# EFR32FG23B021F512IM48 register map
Vendor: Silicon Labs; Series: EFR32; File version: C
CPU: CM33 r0p4, little endian, MPU, FPU, DSP, VTOR, 4 interrupt priority bits, 8 SAU regions
Registers are 32-bit, read-write, reset 0x0 unless marked. A register's access mark holds for its fields unless they carry their own. Offsets are from the block's base; [hi:lo] are bit positions; {n}, {i} and the like mark numbered series; 'fields as' and 'values as' point back to an identical list.

## BURAM_NS — BURAM_NS Registers
Base 0x50080000
Same registers: BURAM_S 0x40080000
{0x0+4i} RET{i}_REG (i=0..31)
  [31:0] RETREG — Latch based Retention register

## BURTC_NS — BURTC_NS Registers
Base 0x50064000
Same registers: BURTC_S 0x40064000
0x00 IPVERSION ro reset 0x1
  [31:0] IPVERSION — IP Version ID
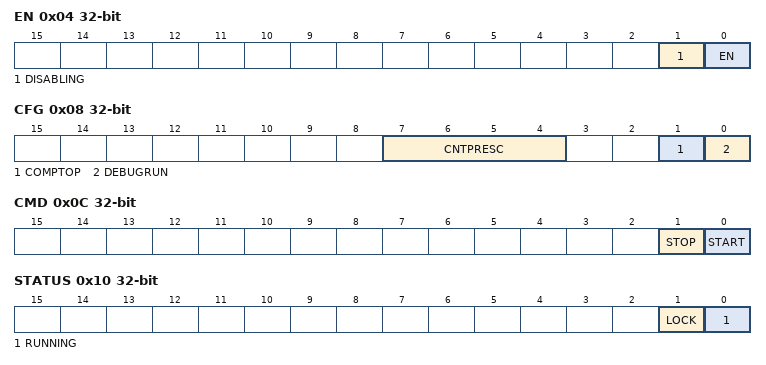
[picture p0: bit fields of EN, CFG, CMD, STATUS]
0x04 EN
  [1] DISABLING ro — Disablement busy status
  [0] EN — BURTC Enable
0x08 CFG
  [7:4] CNTPRESC — Counter prescaler value.
    0=DIV1 (CLK_CNT = (BURTC LF CLK)/1); 1=DIV2 (CLK_CNT = (BURTC LF CLK)/2); 2=DIV4 (CLK_CNT = (BURTC LF CLK)/4); 3=DIV8 (CLK_CNT = (BURTC LF CLK)/8); 4=DIV16 (CLK_CNT = (BURTC LF CLK)/16); 5=DIV32 (CLK_CNT = (BURTC LF CLK)/32); 6=DIV64 (CLK_CNT = (BURTC LF CLK)/64); 7=DIV128 (CLK_CNT = (BURTC LF CLK)/128); 8=DIV256 (CLK_CNT = (BURTC LF CLK)/256); 9=DIV512 (CLK_CNT = (BURTC LF CLK)/512); 10=DIV1024 (CLK_CNT = (BURTC LF CLK)/1024); 11=DIV2048 (CLK_CNT = (BURTC LF CLK)/2048); 12=DIV4096 (CLK_CNT = (BURTC LF CLK)/4096); 13=DIV8192 (CLK_CNT = (BURTC LF CLK)/8192); 14=DIV16384 (CLK_CNT = (BURTC LF CLK)/16384); 15=DIV32768 (CLK_CNT = (BURTC LF CLK)/32768)
  [1] COMPTOP — Compare Channel is Top Value
    0=DISABLE (The top value of the BURTC is 4294967295 (0xFFFFFFFF)); 1=ENABLE (The top value of the BURTC is given by COMP)
  [0] DEBUGRUN — Debug Mode Run Enable
    0=BURTC is frozen in debug mode; 1=BURTC is running in debug mode
0x0C CMD wo
  [1] STOP — Stop BURTC counter
  [0] START — Start BURTC counter
0x10 STATUS ro
  [1] LOCK — Configuration Lock Status
    0=UNLOCKED (All BURTC lockable registers are unlocked.); 1=LOCKED (All BURTC lockable registers are locked.)
  [0] RUNNING — BURTC running status
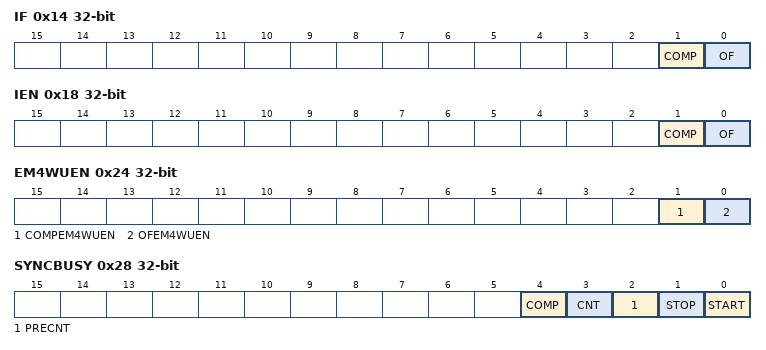
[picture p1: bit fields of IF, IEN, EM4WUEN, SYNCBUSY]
0x14 IF
  [1] COMP — Compare Match Interrupt Flag
  [0] OF — Overflow Interrupt Flag
0x18 IEN
  fields as IF
0x1C PRECNT
  [14:0] PRECNT — Pre-Counter Value
0x20 CNT
  [31:0] CNT — Counter Value
0x24 EM4WUEN
  [1] COMPEM4WUEN — Compare Match EM4 Wakeup Enable
  [0] OFEM4WUEN — Overflow EM4 Wakeup Enable
0x28 SYNCBUSY ro
  [4] COMP — Sync busy for COMP
  [3] CNT — Sync busy for CNT
  [2] PRECNT — Sync busy for PRECNT
  [1] STOP — Sync busy for STOP
  [0] START — Sync busy for START
0x2C LOCK wo reset 0xAEE8
  [15:0] LOCKKEY — Configuration Lock Key
    0xAEE8=UNLOCK (Write to unlock all BURTC lockable registers)
0x30 COMP
  [31:0] COMP — Compare Value

## DMEM_NS — DMEM_NS Registers
Base 0x500B4000
Same registers: DMEM_S 0x400B4000
0x00 IPVERSION ro reset 0x1
  [0] IPVERSION — New BitField
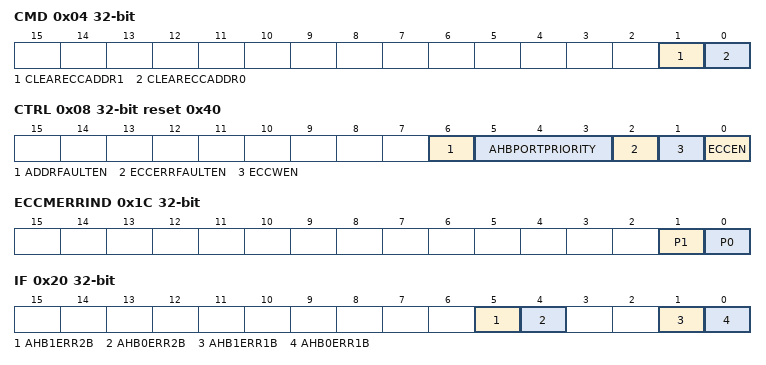
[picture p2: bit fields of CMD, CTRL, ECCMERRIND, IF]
0x04 CMD wo
  [1] CLEARECCADDR1 — Clear ECCERRADDR1
  [0] CLEARECCADDR0 — Clear ECCERRADDR0
0x08 CTRL reset 0x40
  [6] ADDRFAULTEN — Address fault bus fault enable
  [5:3] AHBPORTPRIORITY — AHB port arbitration priority
    0=NONE (No AHB port have raised priority.); 1=PORT0 (AHB port 0 has raised priority.); 2=PORT1 (AHB port 1 has raised priority.)
  [2] ECCERRFAULTEN — ECC Error bus fault enable
  [1] ECCWEN — Enable ECC syndrome writes
  [0] ECCEN — Enable ECC functionality
0x0C ECCERRADDR0 ro
  [31:0] ADDR — ECC Error Address
0x10 ECCERRADDR1 ro
  [31:0] ADDR — ECC Error Address
0x1C ECCMERRIND ro
  [1] P1 — Multiple ECC errors on AHB port 1
  [0] P0 — Multiple ECC errors on AHB port 0
0x20 IF
  [5] AHB1ERR2B — AHB1 2-bit ECC Error Interrupt Flag
  [4] AHB0ERR2B — AHB0 2-bit ECC Error Interrupt Flag
  [1] AHB1ERR1B — AHB1 1-bit ECC Error Interrupt Flag
  [0] AHB0ERR1B — AHB0 1-bit ECC Error Interrupt Flag
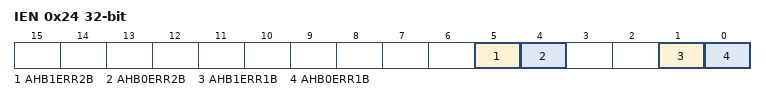
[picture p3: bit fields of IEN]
0x24 IEN
  [5] AHB1ERR2B — AHB1 2-bit ECC Error Interrupt Enable
  [4] AHB0ERR2B — AHB0 2-bit ECC Error Interrupt Enable
  [1] AHB1ERR1B — AHB1 1-bit ECC Error Interrupt Enable
  [0] AHB0ERR1B — AHB0 1-bit ECC Error Interrupt Enable
